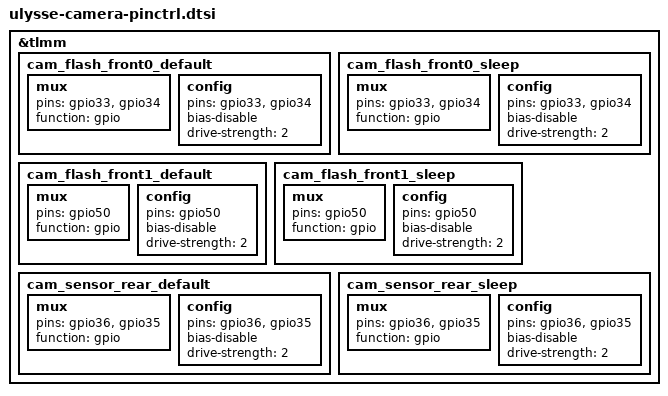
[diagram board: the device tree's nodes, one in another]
/*
 * Copyright (c) 2016-2021, The Linux Foundation. All rights reserved.
 * Copyright (C) 2018 XiaoMi, Inc.
 *
 * This program is free software; you can redistribute it and/or modify
 * it under the terms of the GNU General Public License version 2 and
 * only version 2 as published by the Free Software Foundation.
 *
 * This program is distributed in the hope that it will be useful,
 * but WITHOUT ANY WARRANTY; without even the implied warranty of
 * MERCHANTABILITY or FITNESS FOR A PARTICULAR PURPOSE.  See the
 * GNU General Public License for more details.
 */

&tlmm {
	/delete-node/ cam_sensor_rear_reset;
	/delete-node/ cam_sensor_rear_reset_sleep;
	/delete-node/ cam_sensor_rear_standby;
	/delete-node/ cam_sensor_rear_standby_sleep;
	/delete-node/ cam_sensor_rear_vana;
	/delete-node/ cam_sensor_rear_vana_sleep;

 	cam_flash_front0_default: cam_flash_front0_default {
		mux {
			pins = "gpio33","gpio34";
			function = "gpio";
		};

		config {
			pins = "gpio33","gpio34";
			bias-disable;
			drive-strength = <2>;
		};
	};

	cam_flash_front0_sleep: cam_flash_front0_sleep {
		mux {
			pins = "gpio33","gpio34";
			function = "gpio";
		};

		config {
			pins = "gpio33","gpio34";
			bias-disable;
			drive-strength = <2>;
		};
	};

	cam_flash_front1_default: cam_flash_front1_default {
		mux {
			pins = "gpio50";
			function = "gpio";
		};

		config {
			pins = "gpio50";
			bias-disable;
			drive-strength = <2>;
		};
	};

	cam_flash_front1_sleep: cam_flash_front1_sleep {
		mux {
			pins = "gpio50";
			function = "gpio";
		};

		config {
			pins = "gpio50";
			bias-disable; /* No PULL */
			drive-strength = <2>; /* 2 MA */
		};
	};

	cam_sensor_rear_default: cam_sensor_rear_default {
		/* RESET, STANDBY */
		mux {
				pins = "gpio36", "gpio35";
				function = "gpio";
		};

		config {
				pins = "gpio36","gpio35";
				bias-disable; /* No PULL */
				drive-strength = <2>; /* 2 MA */
		};
	};

	cam_sensor_rear_sleep: cam_sensor_rear_sleep {
		/* RESET, STANDBY */
		mux {
				pins = "gpio36","gpio35";
				function = "gpio";
		};

		config {
				pins = "gpio36","gpio35";
				bias-disable; /* No PULL */
				drive-strength = <2>; /* 2 MA */
		};
	};
};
